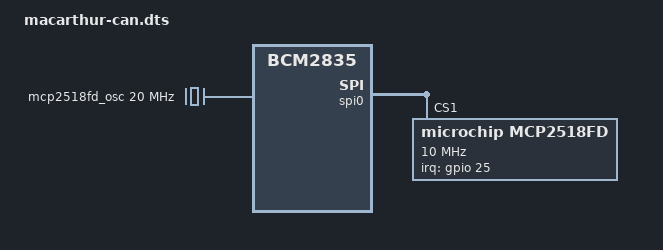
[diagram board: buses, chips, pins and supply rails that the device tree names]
/dts-v1/;
/plugin/;

/*
 * MacArthur HAT – MCP2518FD CAN-FD Controller overlay for VenusOS
 *
 * Source of truth: KiCad schematic
 *   https://github.com/OpenMarine/MacArthur-HAT/tree/main/KiCad
 *
 * Hardware connections (verified from schematic):
 *   SPI0 MOSI   GPIO10 (pin 19)
 *   SPI0 MISO   GPIO9  (pin 21)
 *   SPI0 SCLK   GPIO11 (pin 23)
 *   nCS         GPIO7  (pin 26) = SPI0 CE1 (Linux spi0.1, reg=<1>)
 *                                 Confirmed by OpenPlotter CAN configurator
 *                                 source: "SPI0 CE1" → spi0-1 → CE1 → GPIO7
 *   INT         GPIO25 (pin 22) = active-low interrupt from MCP2518FD
 *   Crystal Y1  20 MHz, 18 pF load capacitance
 *
 * Driver: mcp251xfd  (NOT mcp251x / mcp2515 – those are a different chip)
 * Chip:   MCP2518FD  – also pin-compatible with MCP2517FD
 * CAN:    Used at 250 kbit/s classical CAN for NMEA2000 (no CAN-FD frames)
 *
 * SPI clock: 10 MHz  (MCP2518FD max = 0.85 × 20 MHz = 17 MHz)
 * IRQ type:  level-low (required by the mcp251xfd driver)
 */

/ {
    compatible = "brcm,bcm2835";

    /* 1 – Enable SPI0 controller */
    fragment@0 {
        target = <&spi0>;
        __overlay__ {
            status = "okay";
        };
    };

    /* 2 – Disable the stock spidev on CE1 so mcp251xfd can claim it */
    fragment@1 {
        target = <&spidev1>;
        __overlay__ {
            status = "disabled";
        };
    };

    /* 3 – 20 MHz fixed clock for the MCP2518FD oscillator */
    fragment@2 {
        target-path = "/clocks";
        __overlay__ {
            mcp2518fd_osc: mcp2518fd-osc {
                compatible      = "fixed-clock";
                #clock-cells    = <0>;
                clock-frequency = <20000000>;
            };
        };
    };

    /* 4 – MCP2518FD device on SPI0 CE0 */
    fragment@3 {
        target = <&spi0>;
        __overlay__ {
            #address-cells = <1>;
            #size-cells    = <0>;

            mcp2518fd: mcp2518fd@1 {
                compatible        = "microchip,mcp2518fd";
                reg               = <1>;            /* CE1 = GPIO7 */
                clocks            = <&mcp2518fd_osc>;
                interrupt-parent  = <&gpio>;
                interrupts        = <25 8>;         /* GPIO25, IRQ_TYPE_LEVEL_LOW */
                spi-max-frequency = <10000000>;     /* 10 MHz */
                status            = "okay";
            };
        };
    };
};
